CM_ "AUTOGENERATED FILE, DO NOT EDIT";

CM_ "Imported file _comma.dbc starts here";
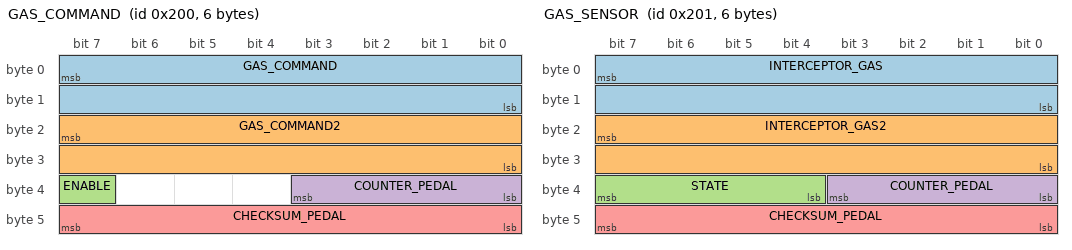
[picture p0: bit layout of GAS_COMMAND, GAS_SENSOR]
BO_ 512 GAS_COMMAND: 6 NEO
 SG_ GAS_COMMAND : 7|16@0+ (0.125677,-75.909) [0|1] "" INTERCEPTOR
 SG_ GAS_COMMAND2 : 23|16@0+ (0.251976,-76.601) [0|1] "" INTERCEPTOR
 SG_ ENABLE : 39|1@0+ (1,0) [0|1] "" INTERCEPTOR
 SG_ COUNTER_PEDAL : 35|4@0+ (1,0) [0|15] "" INTERCEPTOR
 SG_ CHECKSUM_PEDAL : 47|8@0+ (1,0) [0|255] "" INTERCEPTOR

BO_ 513 GAS_SENSOR: 6 INTERCEPTOR
 SG_ INTERCEPTOR_GAS : 7|16@0+ (0.125677,-75.909) [0|1] "" NEO
 SG_ INTERCEPTOR_GAS2 : 23|16@0+ (0.251976,-76.601) [0|1] "" NEO
 SG_ STATE : 39|4@0+ (1,0) [0|15] "" NEO
 SG_ COUNTER_PEDAL : 35|4@0+ (1,0) [0|15] "" NEO
 SG_ CHECKSUM_PEDAL : 47|8@0+ (1,0) [0|255] "" NEO

VAL_ 513 STATE 5 "FAULT_TIMEOUT" 4 "FAULT_STARTUP" 3 "FAULT_SCE" 2 "FAULT_SEND" 1 "FAULT_BAD_CHECKSUM" 0 "NO_FAULT" ;

CM_ "gm_global_a_powertrain.dbc starts here";

VERSION ""

NS_ :

BS_:

BU_: K16_BECM K73_TCIC K9_BCM K43_PSCM K17_EBCM K20_ECM K114B_HPCM NEO K124_ASCM EPB
VAL_TABLE_ TurnSignals 2 "Right Turn" 1 "Left Turn" 0 "None" ;
VAL_TABLE_ Intellibeam 1 "Active" 0 "Inactive" ;
VAL_TABLE_ HighBeamsActive 1 "Active" 0 "Inactive" ;
VAL_TABLE_ HighBeamsTemporary 1 "Active" 0 "Inactive" ;
VAL_TABLE_ ACCLeadCar 1 "Present" 0 "Not Present" ;
VAL_TABLE_ ACCCmdActive 1 "Active" 0 "Inactive" ;
VAL_TABLE_ BrakePedalPressed 1 "Pressed" 0 "Depressed" ;
VAL_TABLE_ DistanceButton 1 "Active" 0 "Inactive" ;
VAL_TABLE_ LKAButton 1 "Active" 0 "Inactive" ;
VAL_TABLE_ ACCButtons 6 "Cancel" 5 "Main" 3 "Set" 2 "Resume" 1 "None" ;
VAL_TABLE_ DriveModeButton 1 "Active" 0 "Inactive" ;
VAL_TABLE_ PRNDL 3 "Reverse" 2 "Drive" 1 "Neutral" 0 "Park" ;
VAL_TABLE_ ESPButton 1 "Active" 0 "Inactive" ;
VAL_TABLE_ DoorStatus 1 "Opened" 0 "Closed" ;
VAL_TABLE_ SeatBeltStatus 1 "Latched" 0 "Unlatched" ;
VAL_TABLE_ LKASteeringCmdActive 1 "Active" 0 "Inactive" ;
VAL_TABLE_ ACCGapLevel 3 "Far" 2 "Med" 1 "Near" 0 "Inactive" ;
VAL_TABLE_ GasRegenCmdActiveInv 1 "Inactive" 0 "Active" ;
VAL_TABLE_ GasRegenCmdActive 1 "Active" 0 "Inactive" ;
VAL_TABLE_ LKATorqueDeliveredStatus 3 "Failed" 2 "Temp. Limited" 1 "Active" 0 "Inactive" ;
VAL_TABLE_ HandsOffSWDetectionStatus 1 "Hands On" 0 "Hands Off" ;
VAL_TABLE_ HandsOffSWDetectionMode 2 "Failed" 1 "Enabled" 0 "Disabled" ;

BO_ 776 UnknownA: 8 NEO
 SG_ UnknownA : 7|64@0+ (1,0) [0|0] "" NEO

BO_ 768 UnknownB: 8 NEO
 SG_ UnknownB : 7|64@0+ (1,0) [0|0] "" NEO

BO_ 883 UnknownC: 8 NEO
 SG_ UnknownC : 7|64@0+ (1,0) [0|0] "" NEO

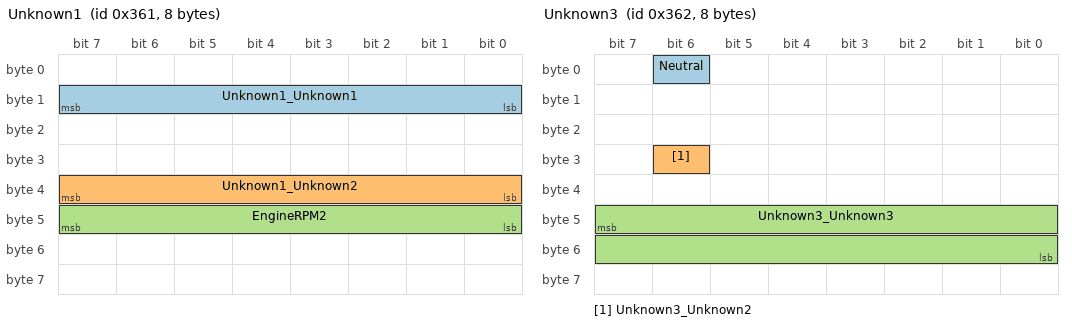
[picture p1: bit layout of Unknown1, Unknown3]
BO_ 865 Unknown1: 8 NEO
 SG_ Unknown1_Unknown1 : 15|8@0+ (1,0) [0|0] "" NEO
 SG_ Unknown1_Unknown2 : 39|8@0+ (1,0) [0|0] "" NEO
 SG_ EngineRPM2 : 47|8@0+ (1,0) [0|0] "" NEO

BO_ 769 Unknown2: 8 NEO
 SG_ Unknown2_Unknown1 : 31|8@0+ (1,0) [0|0] "" NEO

BO_ 866 Unknown3: 8 NEO
 SG_ Neutral : 6|1@0+ (1,0) [0|0] "" NEO
 SG_ Unknown3_Unknown2 : 30|1@0+ (1,0) [0|0] "" NEO
 SG_ Unknown3_Unknown3 : 47|16@0+ (1,0) [0|0] "" NEO

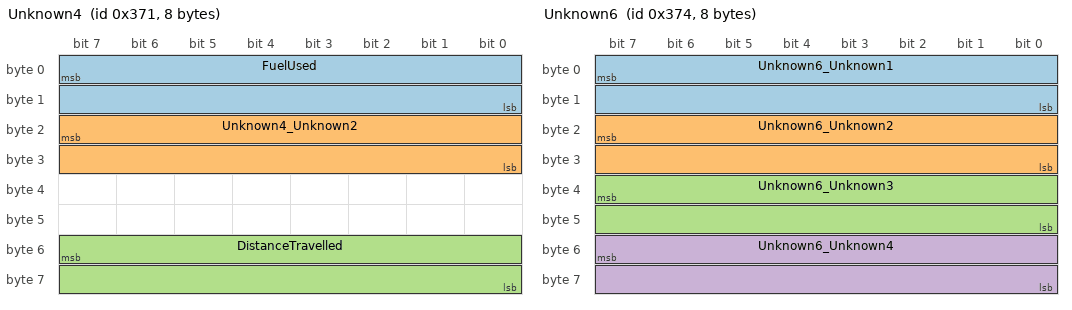
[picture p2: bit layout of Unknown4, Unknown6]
BO_ 881 Unknown4: 8 NEO
 SG_ FuelUsed : 7|16@0+ (1,0) [0|0] "" NEO
 SG_ Unknown4_Unknown2 : 23|16@0+ (1,0) [0|0] "" NEO
 SG_ DistanceTravelled : 55|16@0+ (1,0) [0|0] "" NEO

BO_ 882 Unknown5: 8 NEO
 SG_ Unknown5_Unknown1 : 7|8@0+ (1,0) [0|0] "" NEO
 SG_ Unknown5_Unknown2 : 39|8@0+ (1,0) [0|0] "" NEO

BO_ 884 Unknown6: 8 NEO
 SG_ Unknown6_Unknown1 : 7|16@0+ (1,0) [0|0] "" NEO
 SG_ Unknown6_Unknown2 : 23|16@0+ (1,0) [0|0] "" NEO
 SG_ Unknown6_Unknown3 : 39|16@0+ (1,0) [0|0] "" NEO
 SG_ Unknown6_Unknown4 : 55|16@0+ (1,0) [0|0] "" NEO

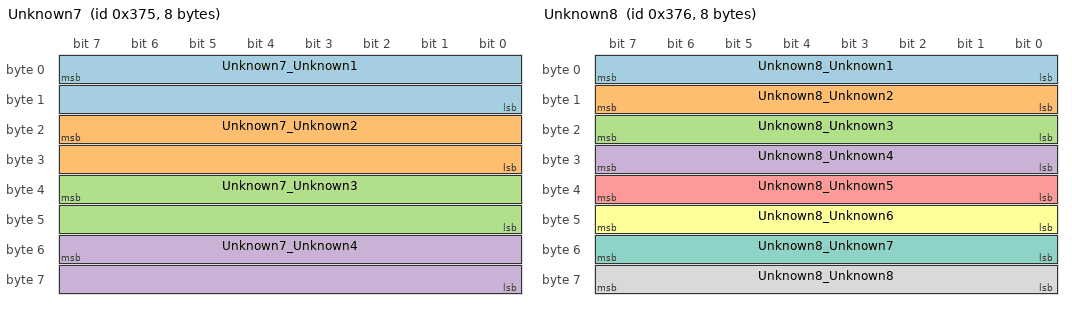
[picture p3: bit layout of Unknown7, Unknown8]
BO_ 885 Unknown7: 8 NEO
 SG_ Unknown7_Unknown1 : 7|16@0+ (1,0) [0|0] "" NEO
 SG_ Unknown7_Unknown2 : 23|16@0+ (1,0) [0|0] "" NEO
 SG_ Unknown7_Unknown3 : 39|16@0+ (1,0) [0|0] "" NEO
 SG_ Unknown7_Unknown4 : 55|16@0+ (1,0) [0|0] "" NEO

BO_ 886 Unknown8: 8 NEO
 SG_ Unknown8_Unknown1 : 7|8@0+ (1,0) [0|0] "" NEO
 SG_ Unknown8_Unknown2 : 15|8@0+ (1,0) [0|0] "" NEO
 SG_ Unknown8_Unknown3 : 23|8@0+ (1,0) [0|0] "" NEO
 SG_ Unknown8_Unknown4 : 31|8@0+ (1,0) [0|0] "" NEO
 SG_ Unknown8_Unknown5 : 39|8@0+ (1,0) [0|0] "" NEO
 SG_ Unknown8_Unknown6 : 47|8@0+ (1,0) [0|0] "" NEO
 SG_ Unknown8_Unknown7 : 55|8@0+ (1,0) [0|0] "" NEO
 SG_ Unknown8_Unknown8 : 63|8@0+ (1,0) [0|0] "" NEO

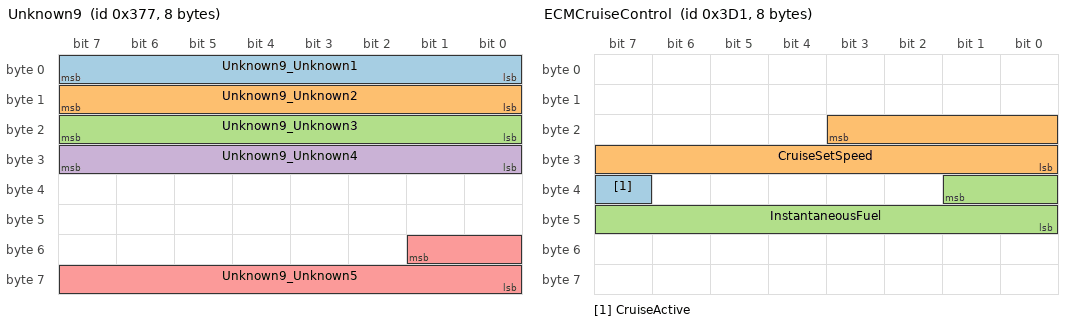
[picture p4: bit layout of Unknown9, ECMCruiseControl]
BO_ 887 Unknown9: 8 NEO
 SG_ Unknown9_Unknown1 : 7|8@0+ (1,0) [0|0] "" NEO
 SG_ Unknown9_Unknown2 : 15|8@0+ (1,0) [0|0] "" NEO
 SG_ Unknown9_Unknown3 : 23|8@0+ (1,0) [0|0] "" NEO
 SG_ Unknown9_Unknown4 : 31|8@0+ (1,0) [0|0] "" NEO
 SG_ Unknown9_Unknown5 : 49|10@0+ (1,0) [0|0] "" NEO

BO_ 977 ECMCruiseControl: 8 K20_ECM
 SG_ CruiseActive : 39|1@0+ (1,0) [0|3] "" NEO
 SG_ CruiseSetSpeed : 19|12@0+ (0.0625,0) [0|0] "km/h" NEO
 SG_ InstantaneousFuel : 33|10@0+ (1,0) [0|0] "" NEO

BO_ 1001 ECMVehicleSpeed: 8 K20_ECM
 SG_ VehicleSpeed : 7|16@0+ (0.015625,0) [0|0] "km/h"  NEO
 SG_ VehicleSpeedLeft : 39|16@0+ (0.01,0) [0|0] "mph" NEO

BO_ 1237 Unknown12: 8 NEO
 SG_ Unknown12_Unknown1 : 15|8@0+ (1,0) [0|0] "" NEO

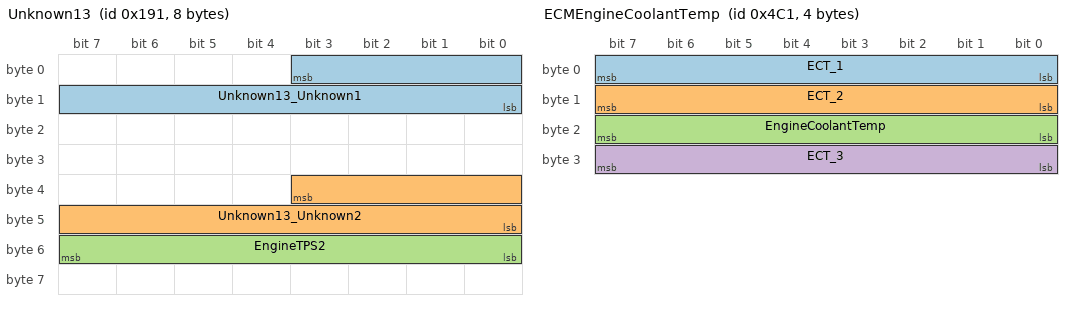
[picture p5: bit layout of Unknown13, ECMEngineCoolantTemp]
BO_ 401 Unknown13: 8 NEO
 SG_ Unknown13_Unknown1 : 3|12@0+ (1,0) [0|0] "" NEO
 SG_ Unknown13_Unknown2 : 35|12@0+ (1,0) [0|0] "" NEO
 SG_ EngineTPS2 : 55|8@0+ (1,0) [0|0] "" NEO

BO_ 1217 ECMEngineCoolantTemp: 4 K20_ECM
 SG_ ECT_1 : 7|8@0+ (1,0) [0|0] ""  NEO
 SG_ ECT_2 : 15|8@0+ (1,0) [0|0] ""  NEO
 SG_ EngineCoolantTemp : 23|8@0+ (1,-40) [0|0] "C"  NEO
 SG_ ECT_3 : 31|8@0+ (1,0) [0|0] ""  NEO

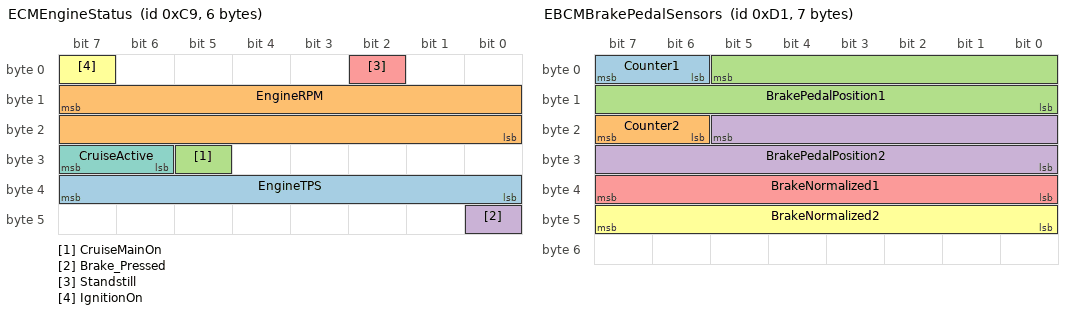
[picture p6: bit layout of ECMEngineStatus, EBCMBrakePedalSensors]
BO_ 201 ECMEngineStatus: 6 K20_ECM
 SG_ EngineTPS : 39|8@0+ (0.392156863,0) [0|100.000000065] "%" NEO
 SG_ EngineRPM : 15|16@0+ (0.25,0) [0|0] "RPM" NEO
 SG_ CruiseMainOn : 29|1@0+ (1,0) [0|1] "" NEO
 SG_ Brake_Pressed : 40|1@0+ (1,0) [0|1] "" NEO
 SG_ Standstill : 2|1@0+ (1,0) [0|1] "" NEO
 SG_ IgnitionOn : 7|1@0+ (1,0) [0|1] "" NEO
 SG_ CruiseActive : 31|2@0+ (1,0) [0|3] "" NEO

BO_ 189 EBCMRegenPaddle: 7 K17_EBCM
 SG_ RegenPaddle : 7|4@0+ (1,0) [0|0] ""  NEO

BO_ 190 ECMAcceleratorPos: 6 K20_ECM
 SG_ BrakePedalPos : 15|8@0+ (1,0) [0|0] "sticky"  NEO
 SG_ GasPedalAndAcc : 23|8@0+ (1,0) [0|0] ""  NEO

BO_ 209 EBCMBrakePedalSensors: 7 K17_EBCM
 SG_ Counter1 : 7|2@0+ (1,0) [0|3] "" XXX
 SG_ Counter2 : 23|2@0+ (1,0) [0|3] "" XXX
 SG_ BrakePedalPosition1 : 5|14@0+ (1,0) [0|16383] "" XXX
 SG_ BrakePedalPosition2 : 21|14@0- (-1,0) [0|16383] "" XXX
 SG_ BrakeNormalized1 : 39|8@0+ (1,0) [0|255] "" XXX
 SG_ BrakeNormalized2 : 47|8@0- (-1,0) [0|255] "" XXX

BO_ 241 EBCMBrakePedalPosition: 6 K17_EBCM
 SG_ BrakePedalPosition : 15|8@0+ (1,0) [0|255] ""  NEO

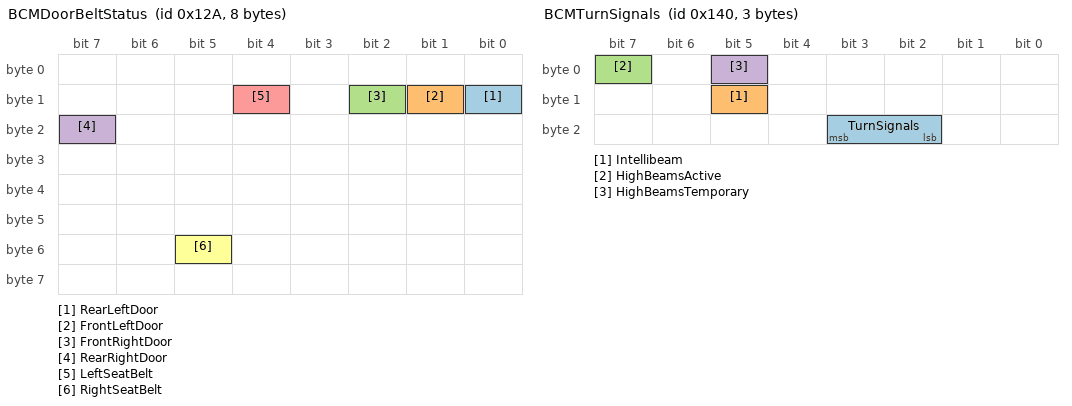
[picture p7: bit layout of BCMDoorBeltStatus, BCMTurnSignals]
BO_ 298 BCMDoorBeltStatus: 8 K9_BCM
 SG_ RearLeftDoor : 8|1@0+ (1,0) [0|0] ""  NEO
 SG_ FrontLeftDoor : 9|1@0+ (1,0) [0|0] ""  NEO
 SG_ FrontRightDoor : 10|1@0+ (1,0) [0|0] ""  NEO
 SG_ RearRightDoor : 23|1@0+ (1,0) [0|0] ""  NEO
 SG_ LeftSeatBelt : 12|1@0+ (1,0) [0|0] ""  NEO
 SG_ RightSeatBelt : 53|1@0+ (1,0) [0|0] ""  NEO

BO_ 309 ECMPRDNL: 8 K20_ECM
 SG_ PRNDL : 2|3@0+ (1,0) [0|0] ""  NEO
 SG_ ESPButton : 4|1@0+ (1,0) [0|1] "" XXX

BO_ 320 BCMTurnSignals: 3 K9_BCM
 SG_ TurnSignals : 19|2@0+ (1,0) [0|0] ""  NEO
 SG_ Intellibeam : 13|1@0+ (1,0) [0|1] "" XXX
 SG_ HighBeamsActive : 7|1@0+ (1,0) [0|1] "" XXX
 SG_ HighBeamsTemporary : 5|1@0+ (1,0) [0|1] "" XXX

BO_ 328 PSCM_148: 1 K43_PSCM

BO_ 381 ESPStatus: 6 K20_ECM
 SG_ TractionControlOn : 5|1@0+ (1,0) [0|0] ""  NEO
 SG_ MSG17D_AccPower : 35|12@0- (1,0) [0|0] ""  NEO

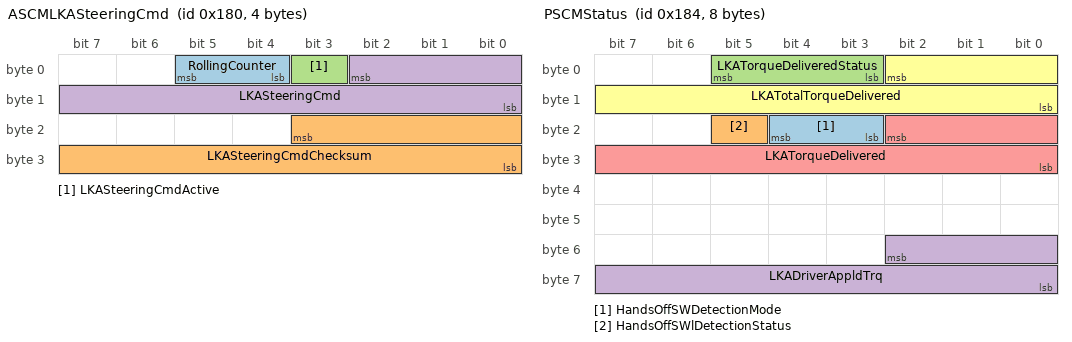
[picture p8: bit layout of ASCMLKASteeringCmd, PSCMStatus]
BO_ 384 ASCMLKASteeringCmd: 4 NEO
 SG_ RollingCounter : 5|2@0+ (1,0) [0|0] ""  NEO
 SG_ LKASteeringCmdChecksum : 19|12@0+ (1,0) [0|0] ""  NEO
 SG_ LKASteeringCmdActive : 3|1@0+ (1,0) [0|0] ""  NEO
 SG_ LKASteeringCmd : 2|11@0- (1,0) [0|0] ""  NEO

BO_ 388 PSCMStatus: 8 K43_PSCM
 SG_ HandsOffSWDetectionMode : 20|2@0+ (1,0) [0|3] "" NEO
 SG_ HandsOffSWlDetectionStatus : 21|1@0+ (1,0) [0|1] "" NEO
 SG_ LKATorqueDeliveredStatus : 5|3@0+ (1,0) [0|7] "" NEO
 SG_ LKADriverAppldTrq : 50|11@0- (0.01,0) [-10.24|10.23] "Nm" NEO
 SG_ LKATorqueDelivered : 18|11@0- (0.01,0) [0|1] "" NEO
 SG_ LKATotalTorqueDelivered : 2|11@0- (0.01,0) [-10.24|10.23] "Nm" NEO

BO_ 417 AcceleratorPedal: 7 XXX
 SG_ AcceleratorPedal : 55|8@0+ (1,0) [0|0] ""  NEO

BO_ 451 GasAndAcc: 8 XXX
 SG_ GasPedalAndAcc2 : 55|8@0+ (1,0) [0|0] ""  NEO

BO_ 452 AcceleratorPedal2: 8 XXX
 SG_ CruiseState : 15|3@0+ (1,0) [0|7] ""  NEO
 SG_ AcceleratorPedal2 : 47|8@0+ (1,0) [0|0] ""  NEO

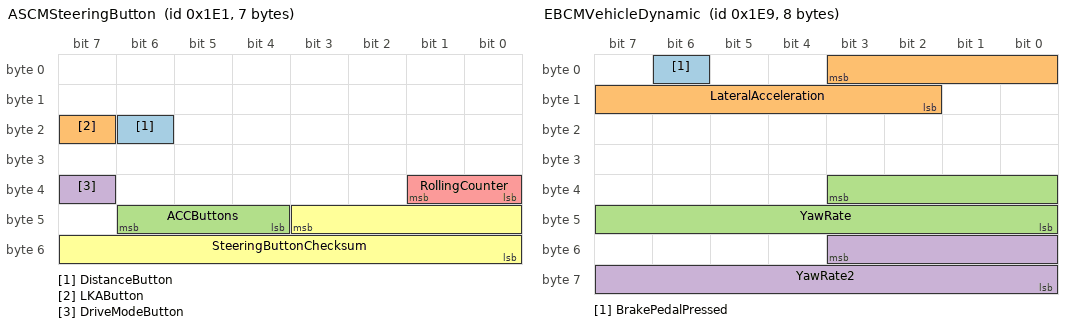
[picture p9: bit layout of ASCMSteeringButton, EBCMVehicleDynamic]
BO_ 481 ASCMSteeringButton: 7 K124_ASCM
 SG_ DistanceButton : 22|1@0+ (1,0) [0|0] ""  NEO
 SG_ LKAButton : 23|1@0+ (1,0) [0|0] ""  NEO
 SG_ ACCButtons : 46|3@0+ (1,0) [0|0] ""  NEO
 SG_ DriveModeButton : 39|1@0+ (1,0) [0|1] "" XXX
 SG_ RollingCounter : 33|2@0+ (1,0) [0|3] "" NEO
 SG_ SteeringButtonChecksum : 43|12@0+ (1,0) [0|255] "" NEO

BO_ 485 PSCMSteeringAngle: 8 K43_PSCM
 SG_ SteeringWheelAngle : 15|16@0- (0.0625,0) [-2047|2047] "deg"  NEO
 SG_ SteeringWheelRate : 27|12@0- (1,0) [-2047|2047] "deg/s"  NEO

BO_ 489 EBCMVehicleDynamic: 8 K17_EBCM
 SG_ BrakePedalPressed : 6|1@0+ (1,0) [0|0] "" NEO
 SG_ LateralAcceleration : 3|10@0- (0.161,0) [-2047|2047] "m/s2" NEO
 SG_ YawRate : 35|12@0- (0.625,0) [0|1] "" NEO
 SG_ YawRate2 : 51|12@0- (0.0625,0) [-2047|2047] "grad/s" NEO

BO_ 352 VehicleIgnition: 5 XXX
 SG_ Ignition : 7|32@0+ (1,0) [0|4294967295] "" XXX

BO_ 497 VehicleIgnitionAlt: 8 XXX
 SG_ Ignition : 5|1@0+ (1,0) [0|1] "" XXX
 SG_ ParkBrake : 36|1@0+ (1,0) [0|3] "" XXX

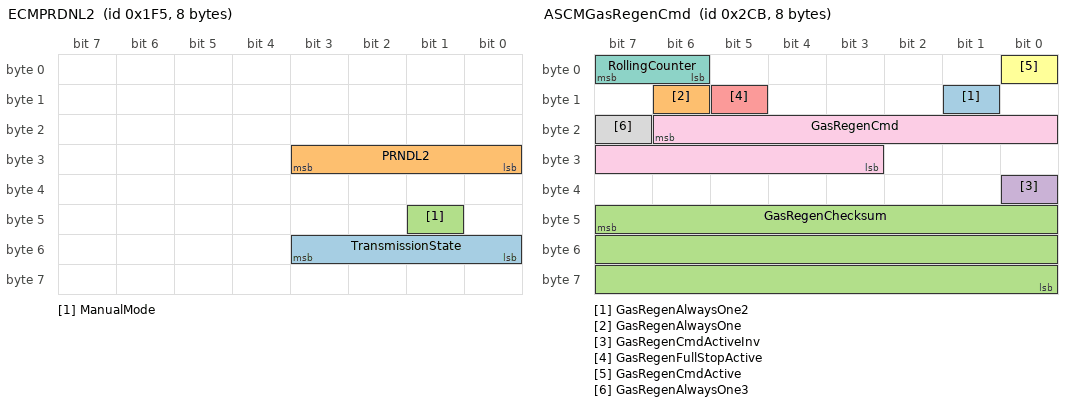
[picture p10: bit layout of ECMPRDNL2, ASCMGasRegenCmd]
BO_ 501 ECMPRDNL2: 8 K20_ECM
 SG_ TransmissionState : 48|4@1+ (1,0) [0|7] "" NEO
 SG_ PRNDL2 : 27|4@0+ (1,0) [0|255] "" NEO
 SG_ ManualMode : 41|1@0+ (1,0) [0|1] "" NEO

BO_ 560 EPBStatus: 8 EPB
 SG_ EPBClosed : 12|1@0+ (1,0) [0|1] ""  NEO

BO_ 711 BECMBatteryVoltageCurrent: 6 K17_EBCM
 SG_ HVBatteryVoltage : 31|12@0+ (0.125,0) [0|511.875] "V"  NEO
 SG_ HVBatteryCurrent : 12|13@0- (0.15,0) [-614.4|614.25] "A"  NEO

BO_ 715 ASCMGasRegenCmd: 8 K124_ASCM
 SG_ GasRegenAlwaysOne2 : 9|1@0+ (1,0) [0|1] ""  NEO
 SG_ GasRegenAlwaysOne : 14|1@0+ (1,0) [0|1] ""  NEO
 SG_ GasRegenChecksum : 47|24@0+ (1,0) [0|0] ""  NEO
 SG_ GasRegenCmdActiveInv : 32|1@0+ (1,0) [0|0] ""  NEO
 SG_ GasRegenFullStopActive : 13|1@0+ (1,0) [0|0] ""  NEO
 SG_ GasRegenCmdActive : 0|1@0+ (1,0) [0|0] ""  NEO
 SG_ RollingCounter : 7|2@0+ (1,0) [0|0] ""  NEO
 SG_ GasRegenAlwaysOne3 : 23|1@0+ (1,0) [0|1] ""  NEO
 SG_ GasRegenCmd : 22|12@0+ (1,0) [0|0] ""  NEO

BO_ 717 ASCM_2CD: 5 K124_ASCM

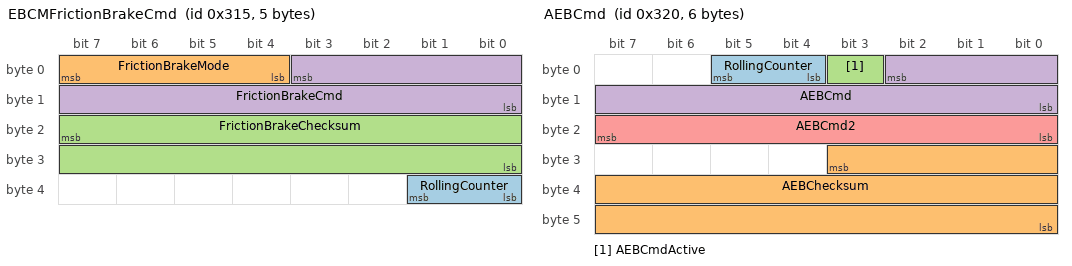
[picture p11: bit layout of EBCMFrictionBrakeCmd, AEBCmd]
BO_ 789 EBCMFrictionBrakeCmd: 5 K124_ASCM
 SG_ RollingCounter : 33|2@0+ (1,0) [0|0] ""  NEO
 SG_ FrictionBrakeMode : 7|4@0+ (1,0) [0|0] ""  NEO
 SG_ FrictionBrakeChecksum : 23|16@0+ (1,0) [0|0] ""  NEO
 SG_ FrictionBrakeCmd : 3|12@0- (1,0) [0|0] ""  NEO

BO_ 800 AEBCmd: 6 K124_ASCM
 SG_ RollingCounter : 5|2@0+ (1,0) [0|3] "" NEO
 SG_ AEBChecksum : 27|20@0+ (1,0) [0|0] "" NEO
 SG_ AEBCmdActive : 3|1@1+ (1,0) [0|1] "" NEO
 SG_ AEBCmd : 2|11@0+ (1,0) [0|0] "" NEO
 SG_ AEBCmd2 : 23|8@0+ (1,0) [0|0] "" NEO

BO_ 810 TCICOnStarGPSPosition: 8 K73_TCIC
 SG_ GPSLongitude : 39|32@0+ (1,-2147483648) [0|0] "milliarcsecond"  NEO
 SG_ GPSLatitude : 7|32@0+ (1,0) [0|0] "milliarcsecond"  NEO

BO_ 840 EBCMWheelSpdFront: 4 K17_EBCM
 SG_ FLWheelSpd : 7|16@0+ (0.0311,0) [0|255] "km/h"  NEO
 SG_ FRWheelSpd : 23|16@0+ (0.0311,0) [0|255] "km/h"  NEO

BO_ 842 EBCMWheelSpdRear: 5 K17_EBCM
 SG_ RLWheelSpd : 7|16@0+ (0.0311,0) [0|255] "km/h"  NEO
 SG_ RRWheelSpd : 23|16@0+ (0.0311,0) [0|255] "km/h"  NEO

BO_ 869 ASCM_365: 4 K124_ASCM

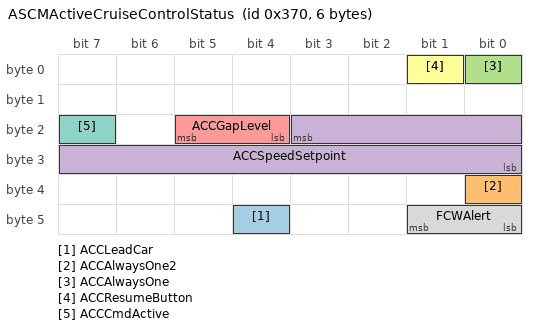
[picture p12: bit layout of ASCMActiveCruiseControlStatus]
BO_ 880 ASCMActiveCruiseControlStatus: 6 K124_ASCM
 SG_ ACCLeadCar : 44|1@0+ (1,0) [0|0] "" Vector__XXX
 SG_ ACCAlwaysOne2 : 32|1@0+ (1,0) [0|0] "" Vector__XXX
 SG_ ACCAlwaysOne : 0|1@0+ (1,0) [0|0] "" Vector__XXX
 SG_ ACCSpeedSetpoint : 19|12@0+ (0.0625,0) [0|255.9375] "km/h"  NEO
 SG_ ACCGapLevel : 21|2@0+ (1,0) [0|0] ""  NEO
 SG_ ACCResumeButton : 1|1@0+ (1,0) [0|0] ""  NEO
 SG_ ACCCmdActive : 23|1@0+ (1,0) [0|0] ""  NEO
 SG_ FCWAlert : 41|2@0+ (1,0) [0|3] "" XXX

BO_ 1033 ASCMKeepAlive: 7 NEO
 SG_ ASCMKeepAliveAllZero : 7|56@0+ (1,0) [0|0] ""  NEO

BO_ 1034 ASCM_40A: 7 K124_ASCM

BO_ 1249 VIN_Part2: 8 K20_ECM
 SG_ VINPart2 : 7|64@0+ (1,0) [0|0] ""  NEO

BO_ 1296 ASCM_510: 4 K124_ASCM

BO_ 1300 VIN_Part1: 8 K20_ECM
 SG_ VINPart1 : 7|64@0+ (1,0) [0|0] ""  NEO

BO_ 1912 PSCM_778: 8 K43_PSCM

BO_ 1930 ASCM_78A: 7 K124_ASCM

BO_TX_BU_ 384 : K124_ASCM,NEO;
BO_TX_BU_ 880 : NEO,K124_ASCM;
BO_TX_BU_ 1033 : K124_ASCM,NEO;
BO_TX_BU_ 715 : NEO,K124_ASCM;
BO_TX_BU_ 789 : NEO,K124_ASCM;
BO_TX_BU_ 800 : NEO,K124_ASCM;

CM_ BU_ K16_BECM "Battery Energy Control Module";
CM_ BU_ K73_TCIC "Telematics Communication Control Module";
CM_ BU_ K9_BCM "Body Control Module";
CM_ BU_ K43_PSCM "Power Steering Control Module";
CM_ BU_ K17_EBCM "Electronic Brake Control Module";
CM_ BU_ K20_ECM "Engine Control Module";
CM_ BU_ K114B_HPCM "Hybrid Powertrain Control Module";
CM_ BU_ NEO "Comma NEO";
CM_ BU_ K124_ASCM "Active Safety Control Module";
CM_ SG_ 381 MSG17D_AccPower "Need to investigate";
CM_ SG_ 190 GasPedalAndAcc "ACC baseline is 62";
CM_ SG_ 352 Ignition "Non-zero when ignition is on";
CM_ SG_ 451 GasPedalAndAcc2 "ACC baseline is 62";
CM_ SG_ 497 Ignition "Describes ignition + preconditioning mode, noisy";
CM_ SG_ 501 PRNDL2 "When ManualMode is Active, Value is 13=L1 12=L2 11=L3 ... 4=L10";
CM_ SG_ 1001 VehicleSpeed "Spinouts show here on 2wd. Speed derived from right front wheel (drive tire)";
BA_DEF_  "UseGMParameterIDs" INT 0 0;
BA_DEF_  "ProtocolType" STRING ;
BA_DEF_  "BusType" STRING ;
BA_DEF_DEF_  "UseGMParameterIDs" 1;
BA_DEF_DEF_  "ProtocolType" "GMLAN";
BA_DEF_DEF_  "BusType" "";
BA_ "BusType" "CAN";
BA_ "UseGMParameterIDs" 0;
VAL_ 481 DistanceButton 1 "Active" 0 "Inactive" ;
VAL_ 481 LKAButton 1 "Active" 0 "Inactive" ;
VAL_ 481 ACCButtons 6 "Cancel" 5 "Main" 3 "Set" 2 "Resume" 1 "None" ;
VAL_ 481 DriveModeButton 1 "Active" 0 "Inactive" ;
VAL_ 452 CruiseState 4 "Standstill" 3 "Faulted" 1 "Active" 0 "Off" ;
VAL_ 309 PRNDL 3 "R" 2 "D" 1 "N" 0 "P" ;
VAL_ 309 ESPButton 1 "Active" 0 "Inactive" ;
VAL_ 384 LKASteeringCmdActive 1 "Active" 0 "Inactive" ;
VAL_ 880 ACCLeadCar 1 "Present" 0 "Not Present" ;
VAL_ 880 ACCGapLevel 3 "Far" 2 "Med" 1 "Near" 0 "Inactive" ;
VAL_ 880 ACCResumeButton 1 "Pressed" 0 "Depressed" ;
VAL_ 880 ACCCmdActive 1 "Active" 0 "Inactive" ;
VAL_ 388 HandsOffSWDetectionMode 2 "Failed" 1 "Enabled" 0 "Disabled" ;
VAL_ 388 HandsOffSWlDetectionStatus 1 "Hands On" 0 "Hands Off" ;
VAL_ 388 LKATorqueDeliveredStatus 3 "Failed" 2 "Temp. Limited" 1 "Active" 0 "Inactive" ;
VAL_ 489 BrakePedalPressed 1 "Pressed" 0 "Depressed" ;
VAL_ 715 GasRegenCmdActiveInv 1 "Inactive" 0 "Active" ;
VAL_ 715 GasRegenCmdActive 1 "Active" 0 "Inactive" ;
VAL_ 320 Intellibeam 1 "Active" 0 "Inactive" ;
VAL_ 320 HighBeamsActive 1 "Active" 0 "Inactive" ;
VAL_ 320 HighBeamsTemporary 1 "Active" 0 "Inactive" ;
VAL_ 501 PRNDL2 6 "L" 4 "D" 3 "N" 2 "R" 1 "P" 0 "Shifting";
VAL_ 501 TransmissionState 11 "Shifting" 10 "Reverse" 9 "Forward" 8 "Disengaged";
VAL_ 501 ManualMode 1 "Active" 0 "Inactive"
